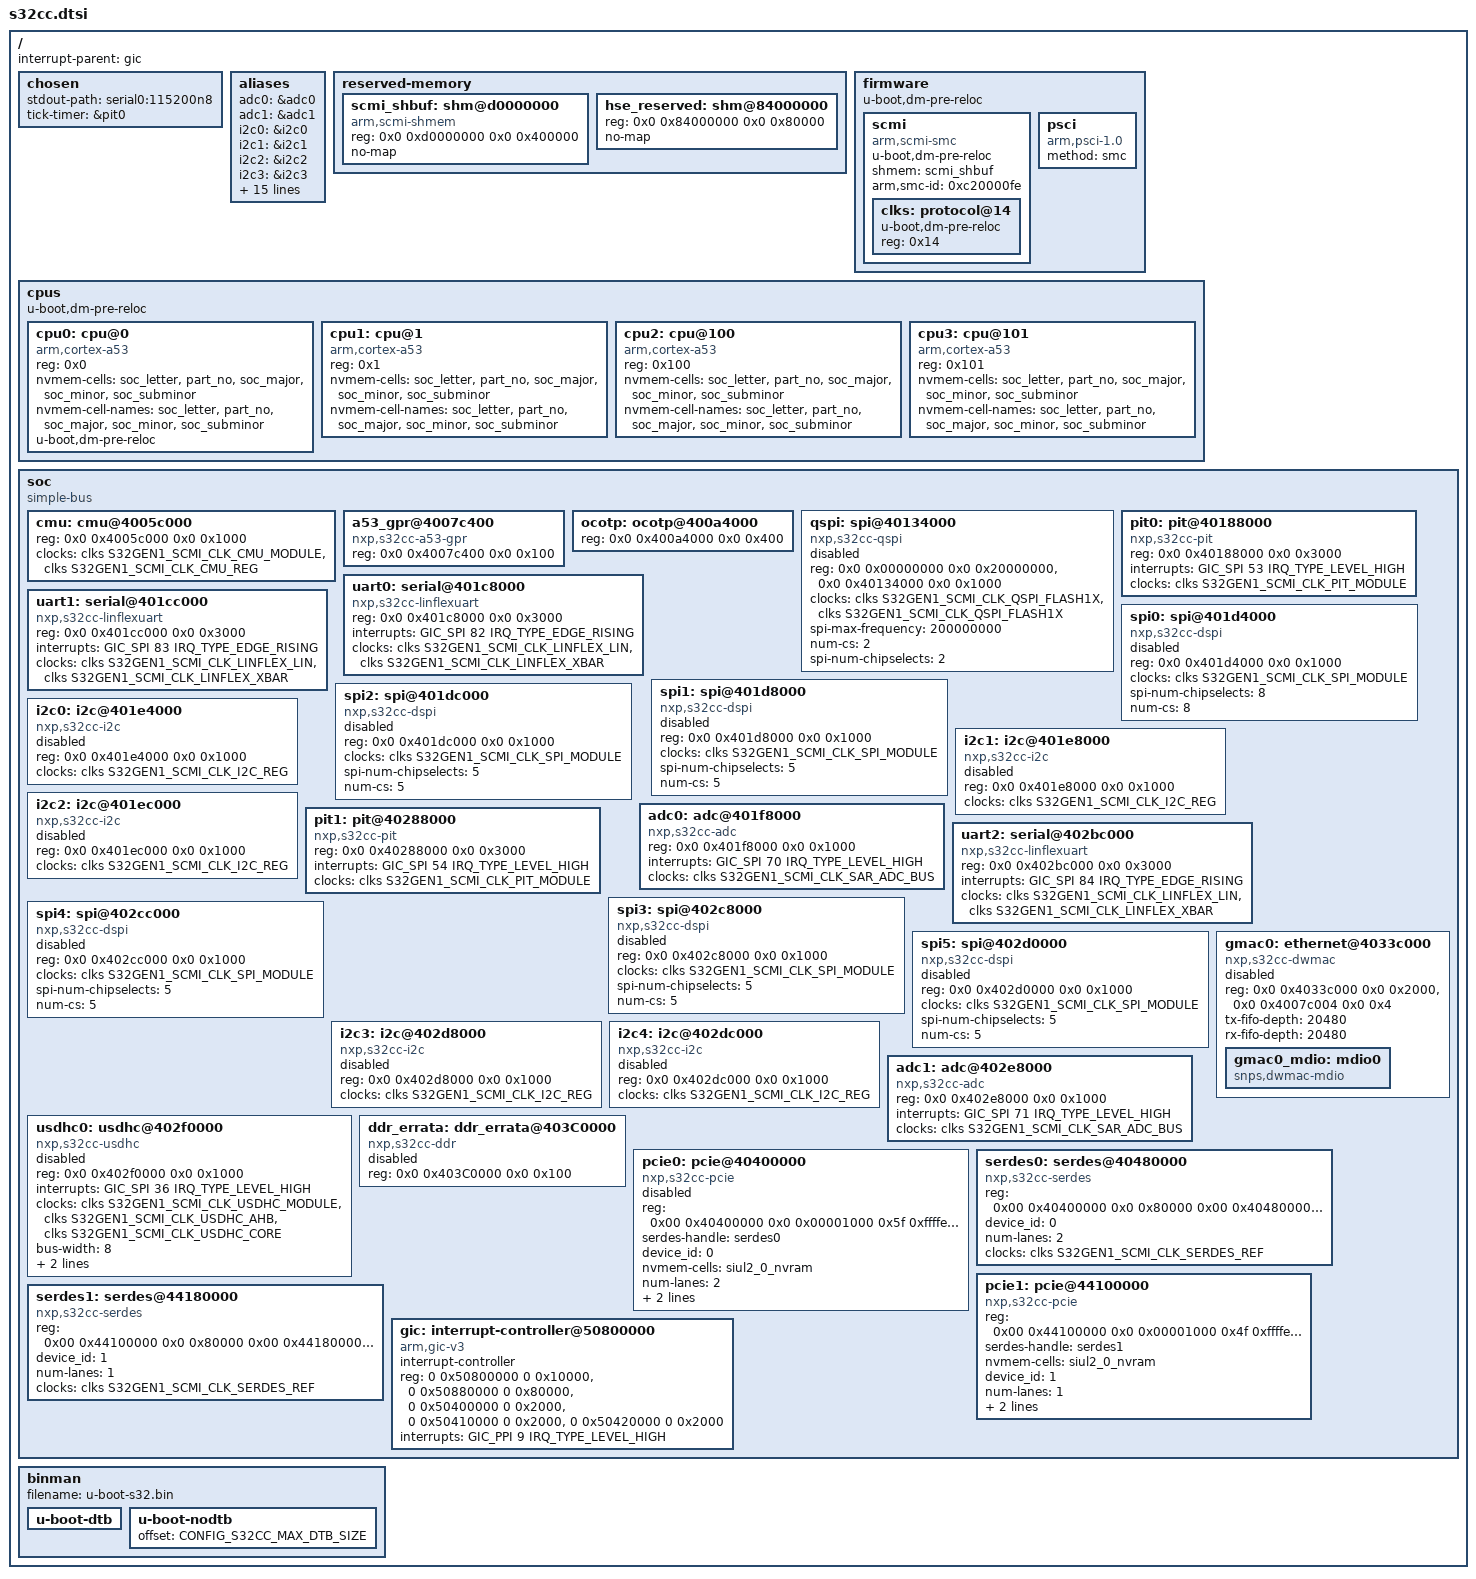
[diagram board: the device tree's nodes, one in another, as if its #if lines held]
// SPDX-License-Identifier: (GPL-2.0+ OR MIT)
/*
 * Device Tree Include file for NXP S32CC family SoCs.
 *
 * Copyright 2019-2022 NXP
 */

#include <dt-bindings/clock/s32gen1-scmi-clock.h>
#include <dt-bindings/interrupt-controller/arm-gic.h>
#include <dt-bindings/interrupt-controller/irq.h>

/ {
	interrupt-parent = <&gic>;
	#address-cells = <2>;
	#size-cells = <2>;

	chosen {
		stdout-path = "serial0:115200n8";
		tick-timer = &pit0;
	};

	aliases {
		adc0 = &adc0;
		adc1 = &adc1;
		i2c0 = &i2c0;
		i2c1 = &i2c1;
		i2c2 = &i2c2;
		i2c3 = &i2c3;
		i2c4 = &i2c4;
		spi0 = &spi0;
		spi1 = &spi1;
		spi2 = &spi2;
		spi3 = &spi3;
		spi4 = &spi4;
		spi5 = &spi5;
		spi6 = &qspi;
		serdes0 = &serdes0;
		pcie0 = &pcie0;
		pcie1 = &pcie1;
		mmc0 = &usdhc0;
		clks = &clks;
		serial0 = &uart0;
		serial1 = &uart1;
	};

	reserved-memory {
		#address-cells = <2>;
		#size-cells = <2>;
		ranges;

		scmi_shbuf: shm@d0000000 {
			compatible = "arm,scmi-shmem";
			reg = <0x0 0xd0000000 0x0 0x400000>;    /* 4 MB */
			no-map;
		};

#ifdef CONFIG_HSE_SECBOOT
		hse_reserved: shm@84000000 {
			reg = <0x0 0x84000000 0x0 0x80000>;	/* 512k */
			no-map;
		};
#endif
	};

	firmware {
		u-boot,dm-pre-reloc;

		scmi: scmi {
			u-boot,dm-pre-reloc;
			compatible = "arm,scmi-smc";
			shmem = <&scmi_shbuf>;
			arm,smc-id = <0xc20000fe>;
			#address-cells = <1>;
			#size-cells = <0>;
			status = "okay";

			clks: protocol@14 {
				u-boot,dm-pre-reloc;

				reg = <0x14>;
				#clock-cells = <1>;
			};
		};

		psci {
			compatible = "arm,psci-1.0";
			method = "smc";
		};
	};

	cpus: cpus {
		#address-cells = <1>;
		#size-cells = <0>;
		u-boot,dm-pre-reloc;

		cpu0: cpu@0 {
			device_type = "cpu";
			compatible = "arm,cortex-a53";
			reg = <0x0>;

			nvmem-cells = <&soc_letter>, <&part_no>,
			    <&soc_major>, <&soc_minor>, <&soc_subminor>;
			nvmem-cell-names = "soc_letter", "part_no",
			    "soc_major", "soc_minor", "soc_subminor";
			u-boot,dm-pre-reloc;
		};

		cpu1: cpu@1 {
			device_type = "cpu";
			compatible = "arm,cortex-a53";
			reg = <0x1>;

			nvmem-cells = <&soc_letter>, <&part_no>,
			    <&soc_major>, <&soc_minor>, <&soc_subminor>;
			nvmem-cell-names = "soc_letter", "part_no",
			    "soc_major", "soc_minor", "soc_subminor";
		};

		cpu2: cpu@100 {
			device_type = "cpu";
			compatible = "arm,cortex-a53";
			reg = <0x100>;

			nvmem-cells = <&soc_letter>, <&part_no>,
			    <&soc_major>, <&soc_minor>, <&soc_subminor>;
			nvmem-cell-names = "soc_letter", "part_no",
			    "soc_major", "soc_minor", "soc_subminor";
		};

		cpu3: cpu@101 {
			device_type = "cpu";
			compatible = "arm,cortex-a53";
			reg = <0x101>;

			nvmem-cells = <&soc_letter>, <&part_no>,
			    <&soc_major>, <&soc_minor>, <&soc_subminor>;
			nvmem-cell-names = "soc_letter", "part_no",
			    "soc_major", "soc_minor", "soc_subminor";
		};
	};

	soc {
		compatible = "simple-bus";
		#address-cells = <2>;
		#size-cells = <2>;
		ranges = <0x0 0x0 0x0 0x0 0x0 0x20000000>,
			 <0x0 0x22C00000 0x0 0x22C00000 0x0 0x4000>,
			 <0x0 0x40000000 0x0 0x40000000 0x0 0x14000000>,
			 <0x48 0x0 0x48 0x0 0x8 0x0>,
			 <0x58 0x0 0x58 0x0 0x8 0x0>;

		cmu: cmu@4005c000 {
			reg = <0x0 0x4005c000 0x0 0x1000>;
			clocks = <&clks S32GEN1_SCMI_CLK_CMU_MODULE>,
				 <&clks S32GEN1_SCMI_CLK_CMU_REG>;
		};

		a53_gpr@4007c400 {
			compatible = "nxp,s32cc-a53-gpr";
			reg = <0x0 0x4007c400 0x0 0x100>;
			status = "okay";
		};

		ocotp: ocotp@400a4000 {
			reg = <0x0 0x400a4000 0x0 0x400>;
			status = "okay";
		};

		qspi: spi@40134000 {
			compatible = "nxp,s32cc-qspi";
			#address-cells = <1>;
			#size-cells = <0>;
			reg = <0x0 0x00000000 0x0 0x20000000>,
				<0x0 0x40134000 0x0 0x1000>;
			reg-names = "QuadSPI-memory", "QuadSPI";
			clock-names = "qspi_en", "qspi";
			clocks = <&clks S32GEN1_SCMI_CLK_QSPI_FLASH1X>,
				 <&clks S32GEN1_SCMI_CLK_QSPI_FLASH1X>;
			spi-max-frequency = <200000000>;
			// For U-Boot 2020.04 only
			num-cs = <2>;
			spi-num-chipselects = <2>;
			status = "disabled";
		};

		pit0: pit@40188000 {
			compatible = "nxp,s32cc-pit";
			reg = <0x0 0x40188000 0x0 0x3000>;
			interrupts = <GIC_SPI 53 IRQ_TYPE_LEVEL_HIGH>;
			clocks = <&clks S32GEN1_SCMI_CLK_PIT_MODULE>;
			clock-names = "pit";
			status = "okay";
		};

		uart0: serial@401c8000 {
			compatible = "nxp,s32cc-linflexuart";
			reg = <0x0 0x401c8000 0x0 0x3000>;
			interrupts = <GIC_SPI 82 IRQ_TYPE_EDGE_RISING>;
			clocks = <&clks S32GEN1_SCMI_CLK_LINFLEX_LIN>,
				 <&clks S32GEN1_SCMI_CLK_LINFLEX_XBAR>;
			clock-names = "lin", "ipg";
		};

		uart1: serial@401cc000 {
			compatible = "nxp,s32cc-linflexuart";
			reg = <0x0 0x401cc000 0x0 0x3000>;
			interrupts = <GIC_SPI 83 IRQ_TYPE_EDGE_RISING>;
			clocks = <&clks S32GEN1_SCMI_CLK_LINFLEX_LIN>,
				 <&clks S32GEN1_SCMI_CLK_LINFLEX_XBAR>;
			clock-names = "lin", "ipg";
		};

		spi0: spi@401d4000 {
			compatible = "nxp,s32cc-dspi";
			reg = <0x0 0x401d4000 0x0 0x1000>;
			clocks = <&clks S32GEN1_SCMI_CLK_SPI_MODULE>;
			clock-names = "dspi";
			spi-num-chipselects = <8>;
			// For U-Boot 2020.04 only
			num-cs = <8>;
			#address-cells = <1>;
			#size-cells = <0>;
			status = "disabled";
		};

		spi1: spi@401d8000 {
			compatible = "nxp,s32cc-dspi";
			reg = <0x0 0x401d8000 0x0 0x1000>;
			clocks = <&clks S32GEN1_SCMI_CLK_SPI_MODULE>;
			clock-names = "dspi";
			spi-num-chipselects = <5>;
			num-cs = <5>;
			#address-cells = <1>;
			#size-cells = <0>;
			// For U-Boot 2020.04 only
			status = "disabled";
		};

		spi2: spi@401dc000 {
			compatible = "nxp,s32cc-dspi";
			reg = <0x0 0x401dc000 0x0 0x1000>;
			clocks = <&clks S32GEN1_SCMI_CLK_SPI_MODULE>;
			clock-names = "dspi";
			spi-num-chipselects = <5>;
			// For U-Boot 2020.04 only
			num-cs = <5>;
			#address-cells = <1>;
			#size-cells = <0>;
			status = "disabled";
		};

		i2c0: i2c@401e4000 {
			compatible = "nxp,s32cc-i2c";
			reg = <0x0 0x401e4000 0x0 0x1000>;
			clocks = <&clks S32GEN1_SCMI_CLK_I2C_REG>;
			clock-names = "ipg";
			#address-cells = <1>;
			#size-cells = <0>;
			status = "disabled";
		};

		i2c1: i2c@401e8000 {
			compatible = "nxp,s32cc-i2c";
			reg = <0x0 0x401e8000 0x0 0x1000>;
			clocks = <&clks S32GEN1_SCMI_CLK_I2C_REG>;
			clock-names = "ipg";
			#address-cells = <1>;
			#size-cells = <0>;
			status = "disabled";
		};

		i2c2: i2c@401ec000 {
			compatible = "nxp,s32cc-i2c";
			reg = <0x0 0x401ec000 0x0 0x1000>;
			clocks = <&clks S32GEN1_SCMI_CLK_I2C_REG>;
			clock-names = "ipg";
			#address-cells = <1>;
			#size-cells = <0>;
			status = "disabled";
		};

		adc0: adc@401f8000 {
			compatible = "nxp,s32cc-adc";
			reg = <0x0 0x401f8000 0x0 0x1000>;
			interrupts = <GIC_SPI 70 IRQ_TYPE_LEVEL_HIGH>;
			clocks = <&clks S32GEN1_SCMI_CLK_SAR_ADC_BUS>;
			clock-names = "adc";
			status = "okay";
		};

		pit1: pit@40288000 {
			compatible = "nxp,s32cc-pit";
			reg = <0x0 0x40288000 0x0 0x3000>;
			interrupts = <GIC_SPI 54 IRQ_TYPE_LEVEL_HIGH>;
			clocks = <&clks S32GEN1_SCMI_CLK_PIT_MODULE>;
			clock-names = "pit";
			status = "okay";
		};

		uart2: serial@402bc000 {
			compatible = "nxp,s32cc-linflexuart";
			reg = <0x0 0x402bc000 0x0 0x3000>;
			interrupts = <GIC_SPI 84 IRQ_TYPE_EDGE_RISING>;
			clocks = <&clks S32GEN1_SCMI_CLK_LINFLEX_LIN>,
				 <&clks S32GEN1_SCMI_CLK_LINFLEX_XBAR>;
			clock-names = "lin", "ipg";
		};

		spi3: spi@402c8000 {
			compatible = "nxp,s32cc-dspi";
			reg = <0x0 0x402c8000 0x0 0x1000>;
			clocks = <&clks S32GEN1_SCMI_CLK_SPI_MODULE>;
			clock-names = "dspi";
			spi-num-chipselects = <5>;
			// For U-Boot 2020.04 only
			num-cs = <5>;
			#address-cells = <1>;
			#size-cells = <0>;
			status = "disabled";
		};

		spi4: spi@402cc000 {
			compatible = "nxp,s32cc-dspi";
			reg = <0x0 0x402cc000 0x0 0x1000>;
			clocks = <&clks S32GEN1_SCMI_CLK_SPI_MODULE>;
			clock-names = "dspi";
			spi-num-chipselects = <5>;
			// For U-Boot 2020.04 only
			num-cs = <5>;
			#address-cells = <1>;
			#size-cells = <0>;
			status = "disabled";
		};

		spi5: spi@402d0000 {
			compatible = "nxp,s32cc-dspi";
			reg = <0x0 0x402d0000 0x0 0x1000>;
			clocks = <&clks S32GEN1_SCMI_CLK_SPI_MODULE>;
			clock-names = "dspi";
			spi-num-chipselects = <5>;
			// For U-Boot 2020.04 only
			num-cs = <5>;
			#address-cells = <1>;
			#size-cells = <0>;
			status = "disabled";
		};

		i2c3: i2c@402d8000 {
			compatible = "nxp,s32cc-i2c";
			reg = <0x0 0x402d8000 0x0 0x1000>;
			clocks = <&clks S32GEN1_SCMI_CLK_I2C_REG>;
			clock-names = "ipg";
			#address-cells = <1>;
			#size-cells = <0>;
			status = "disabled";
		};

		i2c4: i2c@402dc000 {
			compatible = "nxp,s32cc-i2c";
			reg = <0x0 0x402dc000 0x0 0x1000>;
			clocks = <&clks S32GEN1_SCMI_CLK_I2C_REG>;
			clock-names = "ipg";
			#address-cells = <1>;
			#size-cells = <0>;
			status = "disabled";
		};

		adc1: adc@402e8000 {
			compatible = "nxp,s32cc-adc";
			reg = <0x0 0x402e8000 0x0 0x1000>;
			interrupts = <GIC_SPI 71 IRQ_TYPE_LEVEL_HIGH>;
			clocks = <&clks S32GEN1_SCMI_CLK_SAR_ADC_BUS>;
			clock-names = "adc";
			status = "okay";
		};

		usdhc0: usdhc@402f0000 {
			compatible = "nxp,s32cc-usdhc";
			reg = <0x0 0x402f0000 0x0 0x1000>;
			interrupts = <GIC_SPI 36 IRQ_TYPE_LEVEL_HIGH>;
			clocks = <&clks S32GEN1_SCMI_CLK_USDHC_MODULE>,
				 <&clks S32GEN1_SCMI_CLK_USDHC_AHB>,
				 <&clks S32GEN1_SCMI_CLK_USDHC_CORE>;
			clock-names = "ipg", "ahb", "per";
			bus-width = <8>;
			clock-frequency = <0>;	/* updated dynamically if 0 */
			/* The property name is misleading. Actually means DDR52 is
			 * supported at both 1.8V and 3.3V
			 */
			mmc-ddr-1_8v;
			status = "disabled";
		};

		gmac0: ethernet@4033c000 {
			compatible = "nxp,s32cc-dwmac";
			reg = <0x0 0x4033c000 0x0 0x2000>, /* gmac IP */
			      <0x0 0x4007c004 0x0 0x4>;    /* S32 CTRL_STS reg */
			tx-fifo-depth = <20480>;
			rx-fifo-depth = <20480>;
			status = "disabled";
			gmac0_mdio: mdio0 {
				compatible = "snps,dwmac-mdio";
			};
		};

		ddr_errata: ddr_errata@403C0000 {
			compatible = "nxp,s32cc-ddr";
			reg = <0x0 0x403C0000 0x0 0x100>;
			status = "disabled";
		};

		pcie0: pcie@40400000 {
			compatible = "nxp,s32cc-pcie";
			reg = <0x00 0x40400000 0x0 0x00001000   /* dbi registers */
			       /* RC configuration space, 4KB each for cfg0 and cfg1
				* at the end of the outbound memory map
				*/
			       0x5f 0xffffe000 0x0 0x00002000>;
			reg-names = "dbi", "config";
			#address-cells = <3>;
			#size-cells = <2>;
			device_type = "pci";
			serdes-handle = <&serdes0>;
			device_id = <0>;
			nvmem-cells = <&siul2_0_nvram>;

			ranges =
				/* downstream I/O, 64KB and aligned naturally just
				 * before the config space to minimize fragmentation
				 */
				<0x81000000 0x0 0x00000000 0x5f 0xfffe0000 0x0 0x00010000
				/* non-prefetchable memory, with best case size and
				 * alignment
				 */
				 0x82000000 0x0 0x00000000 0x58 0x00000000 0x7 0xfffe0000>;
			num-lanes = <2>;
			link-speed = <3>;
			bus-range = <0x0 0xff>;
			status = "disabled";
		};

		serdes0: serdes@40480000 {
			compatible = "nxp,s32cc-serdes";
			reg = <0x00 0x40400000 0x0 0x80000   /* dbi registers */
			       0x00 0x40480000 0x0 0x04000>; /* serdes registers */
			reg-names = "dbi", "ss";
			#address-cells = <3>;
			#size-cells = <2>;
			device_type = "pci-generic";
			device_id = <0>;
			num-lanes = <2>; /* supports max 2 lanes */
			clocks = <&clks S32GEN1_SCMI_CLK_SERDES_REF>;
		};

		pcie1: pcie@44100000 {
			compatible = "nxp,s32cc-pcie";
			reg = <0x00 0x44100000 0x0 0x00001000   /* dbi registers */
				/* configuration space, 4KB each for cfg0 and cfg1
				 * at the end of the outbound memory map
				 */
				0x4f 0xffffe000 0x0 0x00002000>;
			reg-names = "dbi", "config";
			#address-cells = <3>;
			#size-cells = <2>;
			device_type = "pci";
			serdes-handle = <&serdes1>;
			nvmem-cells = <&siul2_0_nvram>;
			device_id = <1>;
			ranges =
				/* downstream I/O, 64KB and aligned naturally just
				 * before the config space to minimize fragmentation
				 */
				<0x81000000 0x0 0x00000000 0x4f 0xfffe0000 0x0 0x00010000
				/* non-prefetchable memory, with best case size and
				 * alignment
				 */
				 0x82000000 0x0 0x00000000 0x48 0x00000000 0x7 0xfffe0000>;
			num-lanes = <1>;
			link-speed = <3>;
			bus-range = <0x0 0xff>;
			status = "okay";
		};

		serdes1: serdes@44180000 {
			compatible = "nxp,s32cc-serdes";
			reg = <0x00 0x44100000 0x0 0x80000   /* dbi registers */
			       0x00 0x44180000 0x0 0x04000>; /* serdes registers */
			reg-names = "dbi", "ss";
			#address-cells = <3>;
			#size-cells = <2>;
			device_type = "pci-generic";
			device_id = <1>;
			num-lanes = <1>; /* supports 1 lane */
			clocks = <&clks S32GEN1_SCMI_CLK_SERDES_REF>;
			status = "okay";
		};

		gic: interrupt-controller@50800000 {
			compatible = "arm,gic-v3";
			#interrupt-cells = <3>;
			#address-cells = <2>;
			#size-cells = <2>;
			interrupt-controller;
			reg = <0 0x50800000 0 0x10000>, /* GIC Dist */
			      <0 0x50880000 0 0x80000>, /* GICR (RD_base + SGI_base) */
			      <0 0x50400000 0 0x2000>, /* GICC */
			      <0 0x50410000 0 0x2000>, /* GICH */
			      <0 0x50420000 0 0x2000>; /* GICV */
			interrupts = <GIC_PPI 9 IRQ_TYPE_LEVEL_HIGH>;
		};
	};

	binman {
		filename = "u-boot-s32.bin";
		u-boot-dtb {
		};
		u-boot-nodtb {
			offset = <CONFIG_S32CC_MAX_DTB_SIZE>;
		};
	};

};

